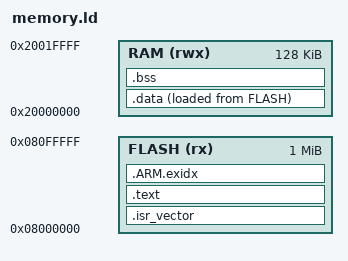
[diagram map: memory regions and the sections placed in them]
ENTRY(Reset_Handler)
MEMORY {
  FLASH (rx) : ORIGIN = 0x08000000, LENGTH = 1024K
  RAM (rwx) : ORIGIN = 0x20000000, LENGTH = 128K
}
SECTIONS {
  .isr_vector : { KEEP(*(.isr_vector)) } > FLASH
  .text : { *(.text*) *(.rodata*) . = ALIGN(4); } > FLASH
  .ARM.exidx : { *(.ARM.exidx*) } > FLASH
  .data : {
    __data_start = .; *(.data*) . = ALIGN(4); __data_end = .;
  } > RAM AT> FLASH
  __data_load = LOADADDR(.data);
  .bss (NOLOAD) : {
    __bss_start = .; *(.bss*) *(COMMON) . = ALIGN(4); __bss_end = .;
  } > RAM
  __stack_top = ORIGIN(RAM) + LENGTH(RAM);
  ASSERT(__bss_end <= __stack_top - 8192, "Insufficient room for stack reserve")
}
